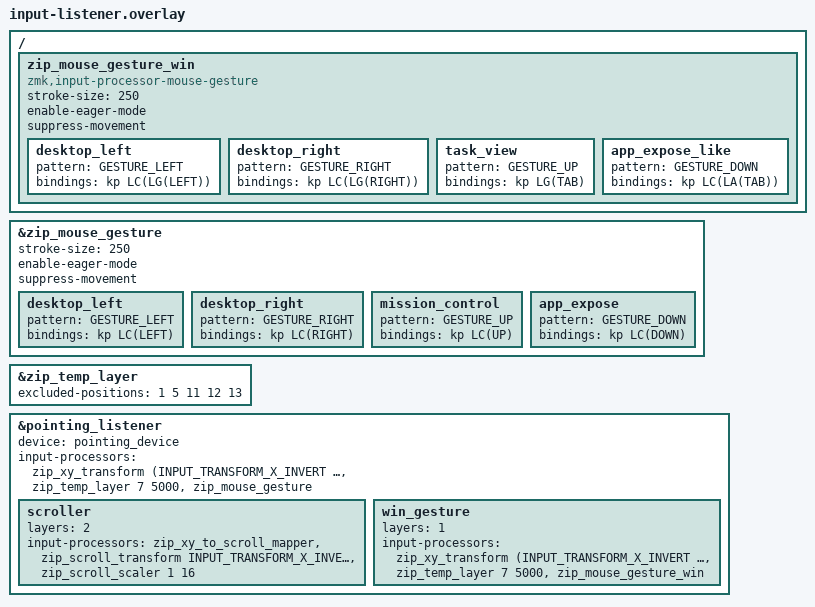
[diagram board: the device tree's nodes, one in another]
#include <dt-bindings/zmk/input_transform.h>
#include <dt-bindings/zmk/mouse-gesture.h>

/*
 * トラックボール側（セントラル）のリスナー。
 * レイヤー2はスクロール、レイヤー1は Windows 用ジェスチャ。
 * 先に書いた override が優先される。Windows ではレイヤー1が常時有効なので、
 * スクロールをジェスチャより前に置く。
 */

/ {
    zip_mouse_gesture_win: zip_mouse_gesture_win {
        compatible = "zmk,input-processor-mouse-gesture";
        #input-processor-cells = <0>;
        stroke-size = <250>;
        enable-eager-mode;
        suppress-movement;

        desktop_left {
            pattern = <GESTURE_LEFT>;
            bindings = <&kp LC(LG(LEFT))>;
        };

        desktop_right {
            pattern = <GESTURE_RIGHT>;
            bindings = <&kp LC(LG(RIGHT))>;
        };

        task_view {
            pattern = <GESTURE_UP>;
            bindings = <&kp LG(TAB)>;
        };

        app_expose_like {
            pattern = <GESTURE_DOWN>;
            bindings = <&kp LC(LA(TAB))>;
        };
    };
};

&zip_mouse_gesture {
    stroke-size = <250>;
    enable-eager-mode;
    suppress-movement;

    desktop_left {
        pattern = <GESTURE_LEFT>;
        bindings = <&kp LC(LEFT)>;
    };

    desktop_right {
        pattern = <GESTURE_RIGHT>;
        bindings = <&kp LC(RIGHT)>;
    };

    mission_control {
        pattern = <GESTURE_UP>;
        bindings = <&kp LC(UP)>;
    };

    app_expose {
        pattern = <GESTURE_DOWN>;
        bindings = <&kp LC(DOWN)>;
    };
};

/* W, Y, S, D, F。S 配列の位置。 */
&zip_temp_layer {
    excluded-positions = <1 5 11 12 13>;
};

&pointing_listener {
    status = "okay";
    device = <&pointing_device>;
    input-processors =
        <&zip_xy_transform (INPUT_TRANSFORM_X_INVERT | INPUT_TRANSFORM_Y_INVERT)>,
        <&zip_temp_layer 7 5000>,
        <&zip_mouse_gesture>;

    scroller {
        layers = <2>;
        input-processors =
            <&zip_xy_to_scroll_mapper>,
            <&zip_scroll_transform INPUT_TRANSFORM_X_INVERT>,
            <&zip_scroll_scaler 1 16>;
    };

    win_gesture {
        layers = <1>;
        input-processors =
            <&zip_xy_transform (INPUT_TRANSFORM_X_INVERT | INPUT_TRANSFORM_Y_INVERT)>,
            <&zip_temp_layer 7 5000>,
            <&zip_mouse_gesture_win>;
    };
};
